# STM32G534 register map
File version: 2.0.0
CPU: CM33 r0p4, little endian, MPU, FPU, 4 interrupt priority bits
Registers are 32-bit, read-write, reset 0x0 unless marked. A register's access mark holds for its fields unless they carry their own. Offsets are from the block's base; [hi:lo] are bit positions; {n}, {i} and the like mark numbered series; 'fields as' and 'values as' point back to an identical list.

## COMP1 — COMP address block description
Base 0x44008400
Same registers: COMP2 0x44008800, COMP3 0x44008C00, COMP4 0x44009000, COMP5 0x44009400, COMP6 0x44009800, COMP7 0x44009C00, COMP8 0x4400A000, COMP{n}_S {0x54008000+0x400*n} (n=1..8)
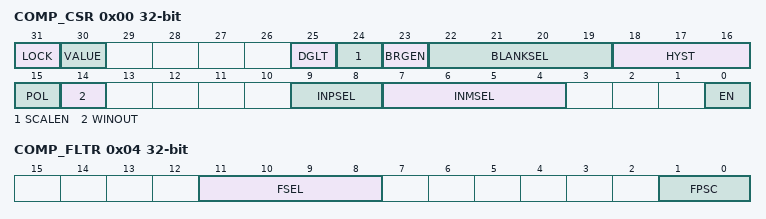
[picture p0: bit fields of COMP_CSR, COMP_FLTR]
0x00 COMP_CSR — Comparator configuration register
  [31] LOCK
    0=COMP_CxCR[31:0] and COMPx_FLTR[31:0] registers are read/write; 1=COMP_CxCR1[31:0] and COMPx_FLTR[31:0] are locked
  [30] VALUE ro — COMPx output value
  [25] DGLT — DEGLITCHER enable
    0=No hysteresis; 1=10 mV hysteresis
  [24] SCALEN — VREFINT scaler enable
    0=No hysteresis; 1=10 mV hysteresis
  [23] BRGEN — VREFINT scaler resistor bridge enable
    0=No hysteresis; 1=10 mV hysteresis
  [22:19] BLANKSEL — Comparator x blanking signal select
    0=No hysteresis; 1=10 mV hysteresis; 2=20 mv hysteresis; 3=30 mV hysteresis; 4=40 mV hysteresis; 5=50 mV hysteresis; 6=60 mV hysteresis; 7=70 mV hysteresis
  [18:16] HYST — Comparator x hysteresis
    values as BLANKSEL
  [15] POL — Comparator x polarity
    0=Non-inverted; 1=Inverted
  [14] WINOUT — COMPx output selector
    0=compless thansub>xless than/sub>_out = compless thansub>xless than/sub>_value; 1=compless thansub>xless than/sub>_out = WINOUT(compless thansub>xless than/sub>)
  [9:8] INPSEL — COMPx channel non-inverting input selection
  [7:4] INMSEL — COMPx channel inverting input selection
  [0] EN — COMPx channel enable
    0=Disable; 1=Enable
0x04 COMP_FLTR — Comparator filter configuration register
  [11:8] FSEL — COMPx digital filter configuration selection
    0=Filter disabled; 1=filter_sampling = comp_pclk, N = 2; 2=filter_sampling = comp_pclk, N = 4; 3=filter_sampling = comp_pclk, N = 8; 4=filter_sampling = filter_clk/2, N = 6; 5=filter_sampling = filter_clk/2, N = 8; 6=filter_sampling = filter_clk/4, N = 6; 7=filter_sampling = filter_clk/4, N = 8; 8=filter_sampling = filter_clk/8, N = 6; 9=filter_sampling = filter_clk/8, N = 8; 10=filter_sampling = filter_clk/16, N = 5; 11=filter_sampling = filter_clk/16, N = 6; 12=filter_sampling = filter_clk/16, N = 8; 13=filter_sampling = filter_clk/32, N = 5; 14=filter_sampling = filter_clk/32, N = 6; 15=filter_sampling = filter_clk/32, N = 8
  [1:0] FPSC — COMPx digital filter configuration selection
    0=filter_clk = comp_pclk; 1=filter_clk = comp_pclk/2; 2=filter_clk = comp_pclk/4; 3=filter_clk = comp_pclk/8

## CRC — CRC address block description
Base 0x40023000
Same registers: CRC_S 0x50023000
0x00 CRC_DR reset 0xFFFFFFFF — CRC data register
  [31:0] DR — Data register bits
0x04 CRC_IDR — CRC independent data register
  [31:0] IDR — General-purpose 32-bit data register bits
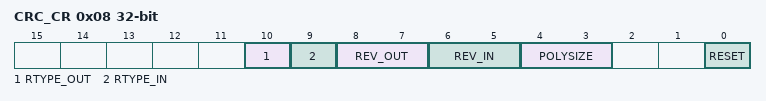
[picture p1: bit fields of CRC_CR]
0x08 CRC_CR — CRC control register
  [10] RTYPE_OUT — Reverse type output
    0=Bit level output; 1=Byte or half-word level output
  [9] RTYPE_IN — Reverse type input
    0=Bit level input; 1=Byte or half-word level input
  [8:7] REV_OUT — Reverse output data
    0=Bit order not affected (RTYPE_OUT=0 or 1); 1=Bit-reversed output format (RTYPE_OUT=0) or half-word reversal done by word (RTYPE_OUT=1); 2=Bit order not affected (RTYPE_OUT=0) or byte reversal done by word (RTYPE_OUT=1); 3=Bit order not affected (RTYPE_OUT=0 or 1)
  [6:5] REV_IN — Reverse input data
    0=Bit order not affected (RTYPE_IN=0 or 1); 1=Bit reversal done by byte (RTYPE_IN=0) or half-word reversal done by word (RTYPE_IN=1); 2=Bit reversal done by half-word (RTYPE_IN=0) or byte reversal done by word (RTYPE_IN=1); 3=Bit reversal done by word (RTYPE_IN=0) or bit order is not affected (RTYPE_IN=1)
  [4:3] POLYSIZE — Polynomial size
    0=32 bit polynomial; 1=16 bit polynomial; 2=8 bit polynomial; 3=7 bit polynomial
  [0] RESET — RESET bit
0x10 CRC_INIT reset 0xFFFFFFFF — CRC initial value
  [31:0] CRC_INIT — Programmable initial CRC value
0x14 CRC_POL reset 0x4C11DB7 — CRC polynomial
  [31:0] POL — Programmable polynomial
